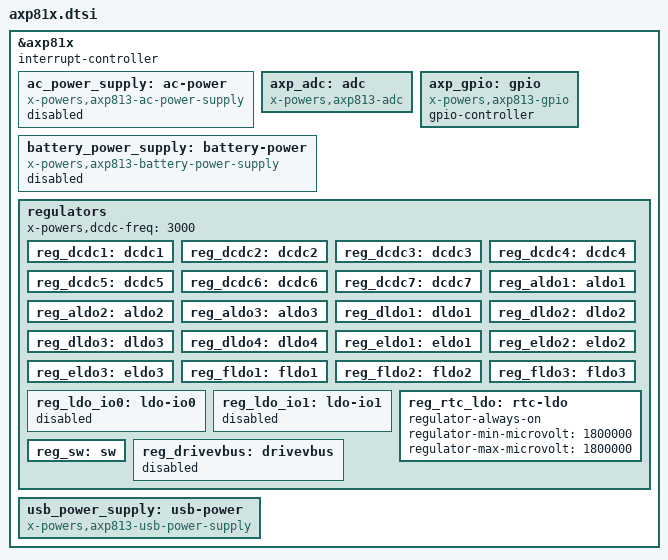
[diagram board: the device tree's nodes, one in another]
&axp81x {
	interrupt-controller;
	#interrupt-cells = <1>;
	ac_power_supply: ac-power {
		compatible = "x-powers,axp813-ac-power-supply";
		status = "disabled";
	};
	axp_adc: adc {
		compatible = "x-powers,axp813-adc";
		#io-channel-cells = <1>;
	};
	axp_gpio: gpio {
		compatible = "x-powers,axp813-gpio";
		gpio-controller;
		#gpio-cells = <2>;
	};
	battery_power_supply: battery-power {
		compatible = "x-powers,axp813-battery-power-supply";
		status = "disabled";
	};
	regulators {
		x-powers,dcdc-freq = <3000>;
		reg_dcdc1: dcdc1 {
		};
		reg_dcdc2: dcdc2 {
		};
		reg_dcdc3: dcdc3 {
		};
		reg_dcdc4: dcdc4 {
		};
		reg_dcdc5: dcdc5 {
		};
		reg_dcdc6: dcdc6 {
		};
		reg_dcdc7: dcdc7 {
		};
		reg_aldo1: aldo1 {
		};
		reg_aldo2: aldo2 {
		};
		reg_aldo3: aldo3 {
		};
		reg_dldo1: dldo1 {
		};
		reg_dldo2: dldo2 {
		};
		reg_dldo3: dldo3 {
		};
		reg_dldo4: dldo4 {
		};
		reg_eldo1: eldo1 {
		};
		reg_eldo2: eldo2 {
		};
		reg_eldo3: eldo3 {
		};
		reg_fldo1: fldo1 {
		};
		reg_fldo2: fldo2 {
		};
		reg_fldo3: fldo3 {
		};
		reg_ldo_io0: ldo-io0 {
			status = "disabled";
		};
		reg_ldo_io1: ldo-io1 {
			status = "disabled";
		};
		reg_rtc_ldo: rtc-ldo {
			regulator-always-on;
			regulator-min-microvolt = <1800000>;
			regulator-max-microvolt = <1800000>;
		};
		reg_sw: sw {
		};
		reg_drivevbus: drivevbus {
			status = "disabled";
		};
	};
	usb_power_supply: usb-power {
		compatible = "x-powers,axp813-usb-power-supply";
	};
};
